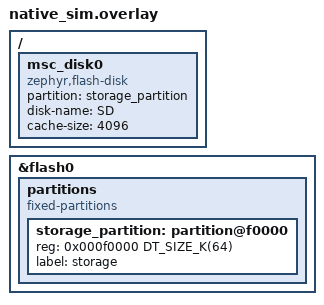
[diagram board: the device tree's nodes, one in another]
/*
 * Copyright (c) 2023 Nordic Semiconductor ASA
 * Copyright (c) 2025 Muhammad Waleed Badar
 *
 * SPDX-License-Identifier: Apache-2.0
 */

/delete-node/ &storage_partition;

&flash0 {
	partitions {
		compatible = "fixed-partitions";
		#address-cells = <1>;
		#size-cells = <1>;

		storage_partition: partition@f0000 {
			reg = <0x000f0000 DT_SIZE_K(64)>;
			label = "storage";
		};
	};
};

/ {
	msc_disk0 {
		compatible = "zephyr,flash-disk";
		partition = <&storage_partition>;
		disk-name = "SD";
		cache-size = <4096>;
		status = "okay";
	};
};
